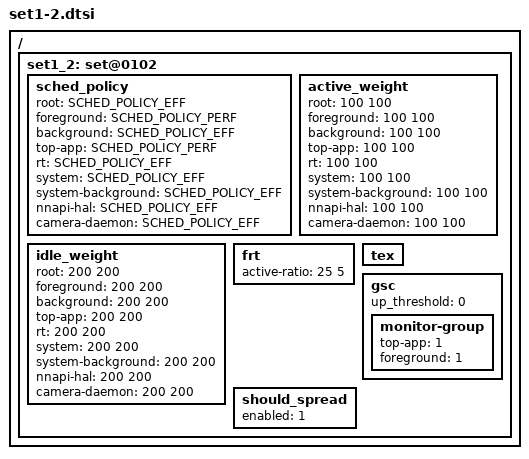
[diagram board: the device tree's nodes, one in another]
/ {
	/* power-scenario mode - app boost */
	set1_2: set@0102 {
		/* schedudling policy */
		sched_policy {
			root			= <SCHED_POLICY_EFF>;
			foreground 		= <SCHED_POLICY_PERF>;
			background		= <SCHED_POLICY_EFF>;
			top-app			= <SCHED_POLICY_PERF>;
			rt			= <SCHED_POLICY_EFF>;
			system			= <SCHED_POLICY_EFF>;
			system-background	= <SCHED_POLICY_EFF>;
			nnapi-hal		= <SCHED_POLICY_EFF>;
			camera-daemon		= <SCHED_POLICY_EFF>;
		};

		/* weight (%) applied to active cpu's efficiency */
		active_weight {			/* LIT BIG */
			root            	= <100 100>;
			foreground      	= <100 100>;
			background      	= <100 100>;
			top-app         	= <100 100>;
			rt			= <100 100>;
			system			= <100 100>;
			system-background	= <100 100>;
			nnapi-hal		= <100 100>;
			camera-daemon		= <100 100>;
		};

		/* weight (%) applied to idle cpu's efficiency */
		idle_weight {	   		/* LIT BIG */
			root            	= <200 200>;
			foreground      	= <200 200>;
			background      	= <200 200>;
			top-app         	= <200 200>;
			rt			= <200 200>;
			system			= <200 200>;
			system-background	= <200 200>;
			nnapi-hal		= <200 200>;
			camera-daemon		= <200 200>;
		};

		frt {	   			/* LIT BIG */
			active-ratio 		= < 25   5>;
		};

		tex { };

		gsc {
			up_threshold = <0>;

			monitor-group {
				top-app = <1>;
				foreground = <1>;
			};
		};

		should_spread {
			enabled = <1>;
		};
	};
};
